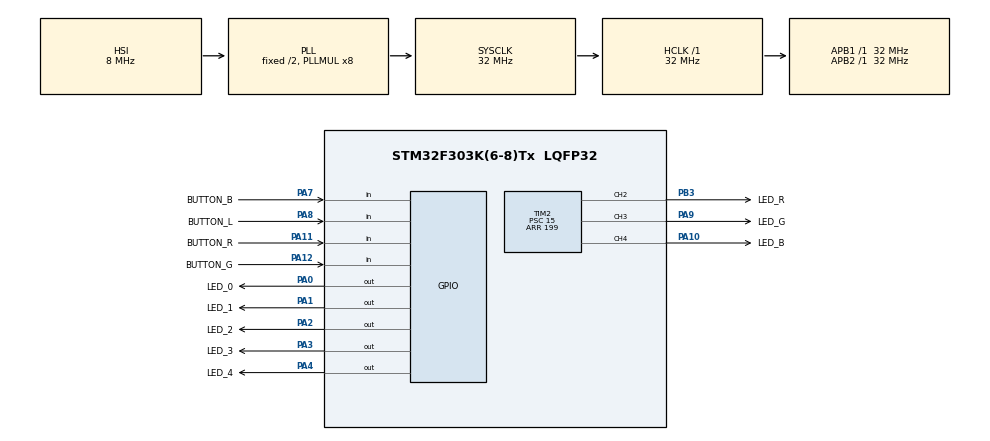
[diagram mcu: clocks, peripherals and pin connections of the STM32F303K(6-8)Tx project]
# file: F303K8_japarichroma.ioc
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Mcu.Family=STM32F3
Mcu.Name=STM32F303K(6-8)Tx
Mcu.Package=LQFP32
NVIC.PriorityGroup=NVIC_PRIORITYGROUP_4
PA0.GPIO_Label=LED_0
PA0.Signal=GPIO_Output
PA1.GPIO_Label=LED_1
PA1.Signal=GPIO_Output
PA10.GPIO_Label=LED_B
PA10.GPIO_ModeDefaultPP=GPIO_MODE_AF_OD
PA10.Signal=S_TIM2_CH4
PA11.GPIO_Label=BUTTON_R
PA11.Signal=GPIO_Input
PA12.GPIO_Label=BUTTON_G
PA12.Signal=GPIO_Input
PA13.Mode=Serial_Wire
PA13.Signal=SYS_JTMS-SWDIO
PA14.Mode=Serial_Wire
PA14.Signal=SYS_JTCK-SWCLK
PA2.GPIO_Label=LED_2
PA2.Signal=GPIO_Output
PA3.GPIO_Label=LED_3
PA3.Signal=GPIO_Output
PA4.GPIO_Label=LED_4
PA4.Signal=GPIO_Output
PA7.GPIO_Label=BUTTON_B
PA7.Signal=GPIO_Input
PA8.GPIO_Label=BUTTON_L
PA8.Signal=GPIO_Input
PA9.GPIO_Label=LED_G
PA9.GPIO_ModeDefaultPP=GPIO_MODE_AF_OD
PA9.Signal=S_TIM2_CH3
PB3.GPIO_Label=LED_R
PB3.GPIO_ModeDefaultPP=GPIO_MODE_AF_OD
PB3.Signal=S_TIM2_CH2
ProjectManager.HeapSize=0x200
ProjectManager.StackSize=0x400
ProjectManager.TargetToolchain=Makefile
RCC.AHBFreq_Value=32000000
RCC.APB1Freq_Value=32000000
RCC.APB1TimFreq_Value=32000000
RCC.APB2Freq_Value=32000000
RCC.APB2TimFreq_Value=32000000
RCC.CortexFreq_Value=32000000
RCC.HCLKFreq_Value=32000000
RCC.HSE_VALUE=8000000
RCC.HSI_VALUE=8000000
RCC.PLLMUL=RCC_PLL_MUL8
RCC.SYSCLKFreq_VALUE=32000000
RCC.SYSCLKSourceVirtual=RCC_SYSCLKSOURCE_PLLCLK
SH.S_TIM2_CH2.0=TIM2_CH2,PWM Generation2 CH2
SH.S_TIM2_CH3.0=TIM2_CH3,PWM Generation3 CH3
SH.S_TIM2_CH4.0=TIM2_CH4,PWM Generation4 CH4
TIM2.Channel-PWM\ Generation2\ CH2=TIM_CHANNEL_2
TIM2.Channel-PWM\ Generation3\ CH3=TIM_CHANNEL_3
TIM2.Channel-PWM\ Generation4\ CH4=TIM_CHANNEL_4
TIM2.Period=199
TIM2.Prescaler=15
VP_TIM2_VS_ClockSourceINT.Mode=Internal
board=custom

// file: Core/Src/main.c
/* USER CODE BEGIN Header */
/**
 ******************************************************************************
 * @file           : main.c
 * @brief          : Main program body
 ******************************************************************************
 * @attention
 *
 * Copyright (c) 2022 STMicroelectronics.
 * All rights reserved.
 *
 * This software is licensed under terms that can be found in the LICENSE file
 * in the root directory of this software component.
 * If no LICENSE file comes with this software, it is provided AS-IS.
 *
 ******************************************************************************
 */
/* USER CODE END Header */
#include "main.h"
#include "tim.h"
#include "gpio.h"

void SystemClock_Config(void);

int main(void)
{

  /* MCU Configuration--------------------------------------------------------*/

  /* Reset of all peripherals, Initializes the Flash interface and the Systick. */
  HAL_Init();

  /* Configure the system clock */
  SystemClock_Config();

  /* Initialize all configured peripherals */
  MX_GPIO_Init();
  MX_TIM2_Init();
  /* USER CODE BEGIN 2 */

  setup();

  /* USER CODE END 2 */

  /* Infinite loop */
  while (1)
  {

    /* USER CODE BEGIN 3 */
    yield();
    loop();
  }
  /* USER CODE END 3 */
}

void SystemClock_Config(void)
{
  RCC_OscInitTypeDef RCC_OscInitStruct = {0};
  RCC_ClkInitTypeDef RCC_ClkInitStruct = {0};

  /** Initializes the RCC Oscillators according to the specified parameters
  * in the RCC_OscInitTypeDef structure.
  */
  RCC_OscInitStruct.OscillatorType = RCC_OSCILLATORTYPE_HSI;
  RCC_OscInitStruct.HSIState = RCC_HSI_ON;
  RCC_OscInitStruct.HSICalibrationValue = RCC_HSICALIBRATION_DEFAULT;
  RCC_OscInitStruct.PLL.PLLState = RCC_PLL_ON;
  RCC_OscInitStruct.PLL.PLLSource = RCC_PLLSOURCE_HSI;
  RCC_OscInitStruct.PLL.PLLMUL = RCC_PLL_MUL8;
  if (HAL_RCC_OscConfig(&RCC_OscInitStruct) != HAL_OK)
  {
    Error_Handler();
  }

  /** Initializes the CPU, AHB and APB buses clocks
  */
  RCC_ClkInitStruct.ClockType = RCC_CLOCKTYPE_HCLK|RCC_CLOCKTYPE_SYSCLK
                              |RCC_CLOCKTYPE_PCLK1|RCC_CLOCKTYPE_PCLK2;
  RCC_ClkInitStruct.SYSCLKSource = RCC_SYSCLKSOURCE_PLLCLK;
  RCC_ClkInitStruct.AHBCLKDivider = RCC_SYSCLK_DIV1;
  RCC_ClkInitStruct.APB1CLKDivider = RCC_HCLK_DIV1;
  RCC_ClkInitStruct.APB2CLKDivider = RCC_HCLK_DIV1;

  if (HAL_RCC_ClockConfig(&RCC_ClkInitStruct, FLASH_LATENCY_1) != HAL_OK)
  {
    Error_Handler();
  }
}

void Error_Handler(void)
{
  __disable_irq();
  while (1)
  {
  }
}
